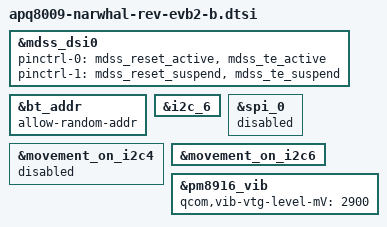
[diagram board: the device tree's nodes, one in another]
/* Copyright (c) 2017, LGE Inc. All rights reserved.
 *
 * This program is free software; you can redistribute it and/or modify
 * it under the terms of the GNU General Public License version 2 and
 * only version 2 as published by the Free Software Foundation.
 *
 * This program is distributed in the hope that it will be useful,
 * but WITHOUT ANY WARRANTY; without even the implied warranty of
 * MERCHANTABILITY or FITNESS FOR A PARTICULAR PURPOSE.  See the
 * GNU General Public License for more details.
 */

#include "apq8009-narwhal.dtsi"

&mdss_dsi0 {
	pinctrl-0 = <&mdss_reset_active &mdss_te_active>;
	pinctrl-1 = <&mdss_reset_suspend &mdss_te_suspend>;

	/delete-property/qcom,platform-enable-gpio;
};

&bt_addr {
	allow-random-addr;
};

&i2c_6 {
	status = "ok";
};

&spi_0 {
	status = "disabled";
};

&movement_on_i2c4 {
	status = "disabled";
};

&movement_on_i2c6 {
	status = "ok";
};

&pm8916_vib {
	qcom,vib-vtg-level-mV = <2900>;
};
